# MAX32550 register map
Vendor: Maxim Integrated; File version: 1.0
Registers are 32-bit, read-write, reset 0x0 unless marked. A register's access mark holds for its fields unless they carry their own. Offsets are from the block's base; [hi:lo] are bit positions; {n}, {i} and the like mark numbered series; 'fields as' and 'values as' point back to an identical list.

## FlashController — Flash Memory Control
Base 0x40029000
0x00 FLSH_ADDR — Flash Write Address
0x04 FLSH_CLKDIV 8-bit reset 0x64 — Flash Clock Divide. The clock (PLL0) is divided by this value to generate a 1 MHz clock for Flash controller.
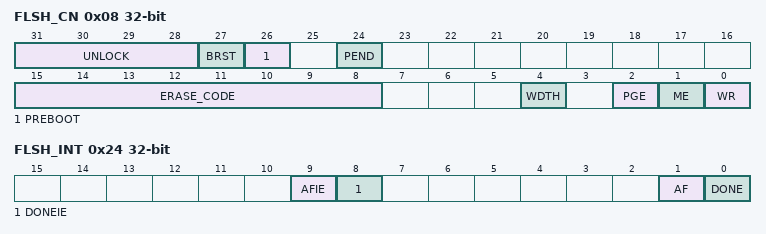
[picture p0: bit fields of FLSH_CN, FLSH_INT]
0x08 FLSH_CN — Flash Control Register
  [31:28] UNLOCK — Flash Unlock. The correct unlock code must be written to these four bits before any Flash write or erase operation is allowed.
    2=unlocked; other=locked
  [27] BRST — Burst Mode Enable
    0=disable; 1=enable
  [26] PREBOOT ro — Preboot Status
    0=idle; 1=busy
  [24] PEND ro — Flash Pending. When Flash operation is in progress (busy), Flash reads and writes will fail. When PEND is set, write to all Flash registers, with exception of the Flash interrupt register, are ignored.
    0=idle; 1=busy
  [15:8] ERASE_CODE — Erase Code. The ERASE_CODE must be set up property before erase operation can be initiated. These bits are automatically cleared after the operation is complete.
    0=nop (No operation); 85=erasePage (Enable Page Erase); 170=eraseAll (Enable Mass Erase. The debug port must be enabled.)
  [4] WDTH — Data Width. This bits selects write data width.
    0=size128 (128-bit); 1=size32 (32-bit)
  [2] PGE — Page Erase. This bit is automatically cleared after the operation.
    0=complete (No operation/complete); 1=Start operation
  [1] ME — Mass Erase. This bit is automatically cleared after the operation.
    0=complete (No operation/complete); 1=Start operation
  [0] WR — Write. This bit is automatically cleared after the operation.
    0=complete (No operation/complete); 1=Start operation
0x24 FLSH_INT — Flash Interrupt Register
  [9] AFIE — Flash Done Interrupt Enable
    0=disable; 1=enable
  [8] DONEIE — Flash Done Interrupt Enable
    0=disable; 1=enable
  [1] AF — Flash Access Fail. This bit is set when an attempt is made to write the flash while the flash is busy or the flash is locked. This bit can only be set to 1 by hardware.
    0=noError; 1=error
  [0] DONE — Flash Done Interrupt. This bit is set to 1 upon Flash write or erase completion.
    0=inactive (No interrupt is pending.); 1=pending (An interrupt is pending.)
{0x30+4i} FLSH_DATA{i} (i=0..3) — Flash Write Data
0x40 ACNTL wo — Access Control Register. Writing the ACNTL register with the following values in the order shown, allows read and write access to the system and user Information block: pflc->acntl = 0x3a7f5ca3; pflc->acntl = 0xa1e34f20; pflc->acntl = 0x9608b2c1. When unlocked, a write of any word will disable access to system and user information block. Readback of this register is always zero.

## MagneticStripeReader
Base 0x4002B000
0x00 DSPADDR 8-bit — MSR Indirect Address Register Access. Indirectly access MSR settings registers by writing the index to this register. The register values are accessible by reading the DSPDATA register.
  [7:0] ADDR — MSR Indirect Address Register Access
    0=t13Scale (Track 1 and 3 scale factor); 1=t2Scale (Track 2 scale factor); 2=t13ZctFast (Zero Cross Threshold Fast for Tracks 1 and 3); 3=t13ZctMid (Zero Cross Threshold Middle for Tracks 1 and 3); 4=t13ZctSlow (Zero Cross Threshold Slow for Tracks 1 and 3); 5=t2ZctFast (Zero Cross Threshold Fast for Track 2); 6=t2ZctMid (Zero Cross Threshold Middle for Track 2); 7=t2ZctSlow (Zero Cross Threshold Slow for Track 2); 8=startPcnt (Leading 0 Detection Count); 9=t1DataCnt (Track 1 Data Count); 10=t2DataCnt (Track 2 Data Count); 11=t3DataCnt (Track 3 Data Count); 18=adcCfg (ADC Configuration)
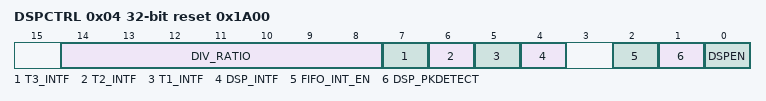
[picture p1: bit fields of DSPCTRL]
0x04 DSPCTRL reset 0x1A00 — MSR DSP Control Register
  [14:8] DIV_RATIO — ADC clock divide ratio. ADC_CLK freq. = PCLK freq. / (DIV_RATIO + 1)
  [7] T3_INTF — T3 FIFO Interrupt Flag. Set by hardware when FIFO is ready for reading. Can be set or cleared by software.
    0=inactive (No interrupt is pending.); 1=pending (An interrupt is pending.)
  [6] T2_INTF — T2 FIFO Interrupt Flag. Set by hardware when FIFO is ready for reading. Can be set or cleared by software.
    values as T3_INTF
  [5] T1_INTF — T1 FIFO Interrupt Flag. Set by hardware when FIFO is ready for reading. Can be set or cleared by software.
    values as T3_INTF
  [4] DSP_INTF — DSP Interrupt Flag. Set to 1 by hardware when swipe is complete. Can be set or cleared by software.
    values as T3_INTF
  [2] FIFO_INT_EN — DSP FIFO Interrupt Enable. Enable the FIFO To cause an interrupt when ready to be read.
    0=disable; 1=enable
  [1] DSP_PKDETECT — DSP Peak Detect Threshold Mode
    0=variable (Select Variable Threshold Mode); 1=fixed (Select Fixed Threshold Mode)
  [0] DSPEN — DSP Enable. Setting this bit to 1 enables the DSP Functionality. Clearing this bit to 0 disables the DSP.
    0=disable; 1=enable
0x08 DSPDATA reset not defined — MSR Indirect Data Register. Indirectly access MSR settings registers by access this register. This register represents an index register whose index is written to DSPADDR register.
{0x8+4i} T{i}FIFO (i=1..3) 16-bit ro — Track FIFO Data Output Register
